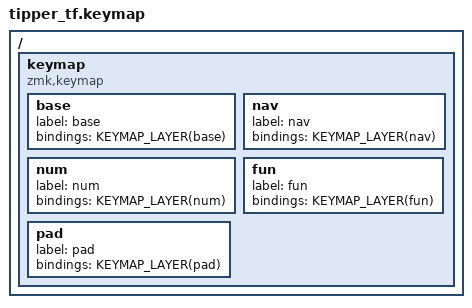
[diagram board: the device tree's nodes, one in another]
/*
 * Tipper TF (weteor) — thin keymap. Wireless nRF52840 split-unibody, 34 keys:
 * 3x5 + 2 thumbs/hand, contiguous 0..33, so it reuses the shared adapter
 * geom_3x5_2.h (same as cb34s / KLOTZ / sweep / El Chibre). The board itself is
 * vendored (HWv2-migrated) under boards/shields/tipper_tf/, including its 1.54"
 * GoodDisplay epaper (JD79653 driver vendored under drivers/display/). All key
 * content lives in config/shared/.
 */

#include <behaviors.dtsi>
#include <dt-bindings/zmk/keys.h>
#include <dt-bindings/zmk/bt.h>
#include <dt-bindings/zmk/outputs.h>

#include "geometry/geom_3x5_2.h"

#include "shared/keys_de.h"
#include "shared/settings.dtsi"
#include "shared/behaviors.dtsi"
#include "shared/macros.dtsi"
#include "shared/combos.dtsi"
#include "shared/core_blocks.dtsi"

/ {
    keymap {
        compatible = "zmk,keymap";

        base { label = "base"; bindings = <KEYMAP_LAYER(base)>; };
        nav  { label = "nav";  bindings = <KEYMAP_LAYER(nav)>;  };
        num  { label = "num";  bindings = <KEYMAP_LAYER(num)>;  };
        fun  { label = "fun";  bindings = <KEYMAP_LAYER(fun)>;  };
        pad  { label = "pad";  bindings = <KEYMAP_LAYER(pad)>;  };
    };
};
